# CY8C5868AXI_LP032 register map
File version: 0.1
Registers are 8-bit, read-write, no defined reset value unless marked. A register's access mark holds for its fields unless they carry their own. Offsets are from the block's base; [hi:lo] are bit positions.

## DOD_PWM_3
Base 0x400043A3
0x00 DOD_PWM_3_GLOBAL_ENABLE — PM.ACT.CFG
  [3:0] en_timer — Enable timer/counters.
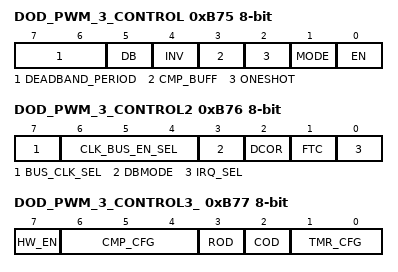
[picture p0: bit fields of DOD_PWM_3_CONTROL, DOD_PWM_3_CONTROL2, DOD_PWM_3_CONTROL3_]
0xB75 DOD_PWM_3_CONTROL — TMRx.CFG0
  [7:6] DEADBAND_PERIOD
  [5] DB — Deadband mode--Deadband phases phi1 and phi2 are outputted on CMP and TC output pins respectively.
    0=Timer (CMP and TC are output.); 1=Deadband (PHI1 (instead of CMP) and PHI2 (instead of TC) are output.)
  [4] INV — Invert sense of TIMEREN signal
  [3] CMP_BUFF — Buffer compare register. Compare register updates only on timer terminal count.
  [2] ONESHOT — Timer stops upon reaching stop condition defined by TMR_CFG bits. Can be restarted by asserting TIMER RESET or disabling and re-enabling block.
  [1] MODE — Mode. (0 = Timer; 1 = Comparator)
    0=Timer mode. CNT/CMP register holds timer count value.; 1=Comparator mode. CNT/CMP register holds comparator threshold value.
  [0] EN — Enables timer/comparator.
0xB76 DOD_PWM_3_CONTROL2 — TMRx.CFG1
  [7] BUS_CLK_SEL — Bus Clock selection.
  [6:4] CLK_BUS_EN_SEL — Digital Global Clock selection.
  [3] DBMODE — Deadband mode (asynchronous/synchronous). CMP output pin is also affected when not in deadband mode (CFG0.DEADBAND).
  [2] DCOR — Disable Clear on Read (DCOR) of Status Register SR0.
  [1] FTC — First Terminal Count (FTC). Setting this bit forces a single pulse on the TC pin when first enabled.
    0=Disable_FTC (Disable the single cycle pulse, which signifies the timer is starting.); 1=Enable_FTC (Enable the single cycle pulse, which signifies the timer is starting.)
  [0] IRQ_SEL — Irq selection. (0 = raw interrupts; 1 = status register interrupts)
0xB77 DOD_PWM_3_CONTROL3_ — TMRx.CFG2
  [7] HW_EN — When set Timer Enable controls counting.
  [6:4] CMP_CFG — Comparator configurations
    0=Equal (Compare Equal); 1=Less_than (Compare Less Than); 2=Less_than_or_equal (Compare Less Than or Equal .); 3=Greater (Compare Greater Than .); 4=Greater_than_or_equal (Compare Greater Than or Equal)
  [3] ROD — Reset On Disable (ROD). Resets internal state of output logic
  [2] COD — Clear On Disable (COD). Clears or gates outputs to zero.
  [1:0] TMR_CFG — Timer configuration (MODE = 0): 000 = Continuous; 001 = Pulsewidth; 010 = Period; 011 = Stop on IRQ
    0=Continuous (Timer runs while EN bit of CFG0 register is set to '1'.); 1=Pulsewidth (Timer runs from positive to negative edge of TIMEREN.); 2=Period (Timer runs from positive to positive edge of TIMEREN.); 3=Irq (Timer runs until IRQ.)
0xB79 DOD_PWM_3_PERIOD — TMRx.PER0 - Assigned Period
0xB7B DOD_PWM_3_COMPARE — TMRx.CNT_CMP0 - Assigned Compare Value

## DOD_PWM_1
Base 0x400043A3
0x00 DOD_PWM_1_GLOBAL_ENABLE — PM.ACT.CFG
  [3:0] en_timer — Enable timer/counters.
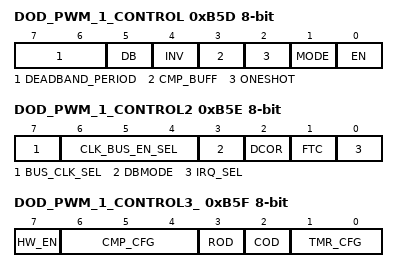
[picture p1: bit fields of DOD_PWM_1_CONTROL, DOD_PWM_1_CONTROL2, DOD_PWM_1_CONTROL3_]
0xB5D DOD_PWM_1_CONTROL — TMRx.CFG0
  [7:6] DEADBAND_PERIOD
  [5] DB — Deadband mode--Deadband phases phi1 and phi2 are outputted on CMP and TC output pins respectively.
    0=Timer (CMP and TC are output.); 1=Deadband (PHI1 (instead of CMP) and PHI2 (instead of TC) are output.)
  [4] INV — Invert sense of TIMEREN signal
  [3] CMP_BUFF — Buffer compare register. Compare register updates only on timer terminal count.
  [2] ONESHOT — Timer stops upon reaching stop condition defined by TMR_CFG bits. Can be restarted by asserting TIMER RESET or disabling and re-enabling block.
  [1] MODE — Mode. (0 = Timer; 1 = Comparator)
    0=Timer mode. CNT/CMP register holds timer count value.; 1=Comparator mode. CNT/CMP register holds comparator threshold value.
  [0] EN — Enables timer/comparator.
0xB5E DOD_PWM_1_CONTROL2 — TMRx.CFG1
  [7] BUS_CLK_SEL — Bus Clock selection.
  [6:4] CLK_BUS_EN_SEL — Digital Global Clock selection.
  [3] DBMODE — Deadband mode (asynchronous/synchronous). CMP output pin is also affected when not in deadband mode (CFG0.DEADBAND).
  [2] DCOR — Disable Clear on Read (DCOR) of Status Register SR0.
  [1] FTC — First Terminal Count (FTC). Setting this bit forces a single pulse on the TC pin when first enabled.
    0=Disable_FTC (Disable the single cycle pulse, which signifies the timer is starting.); 1=Enable_FTC (Enable the single cycle pulse, which signifies the timer is starting.)
  [0] IRQ_SEL — Irq selection. (0 = raw interrupts; 1 = status register interrupts)
0xB5F DOD_PWM_1_CONTROL3_ — TMRx.CFG2
  [7] HW_EN — When set Timer Enable controls counting.
  [6:4] CMP_CFG — Comparator configurations
    0=Equal (Compare Equal); 1=Less_than (Compare Less Than); 2=Less_than_or_equal (Compare Less Than or Equal .); 3=Greater (Compare Greater Than .); 4=Greater_than_or_equal (Compare Greater Than or Equal)
  [3] ROD — Reset On Disable (ROD). Resets internal state of output logic
  [2] COD — Clear On Disable (COD). Clears or gates outputs to zero.
  [1:0] TMR_CFG — Timer configuration (MODE = 0): 000 = Continuous; 001 = Pulsewidth; 010 = Period; 011 = Stop on IRQ
    0=Continuous (Timer runs while EN bit of CFG0 register is set to '1'.); 1=Pulsewidth (Timer runs from positive to negative edge of TIMEREN.); 2=Period (Timer runs from positive to positive edge of TIMEREN.); 3=Irq (Timer runs until IRQ.)
0xB61 DOD_PWM_1_PERIOD — TMRx.PER0 - Assigned Period
0xB63 DOD_PWM_1_COMPARE — TMRx.CNT_CMP0 - Assigned Compare Value

## DOD_PWM_4
Base 0x400043A3
0x00 DOD_PWM_4_GLOBAL_ENABLE — PM.ACT.CFG
  [3:0] en_timer — Enable timer/counters.
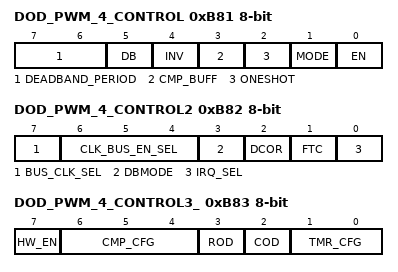
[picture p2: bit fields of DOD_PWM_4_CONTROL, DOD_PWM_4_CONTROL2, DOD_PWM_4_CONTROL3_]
0xB81 DOD_PWM_4_CONTROL — TMRx.CFG0
  [7:6] DEADBAND_PERIOD
  [5] DB — Deadband mode--Deadband phases phi1 and phi2 are outputted on CMP and TC output pins respectively.
    0=Timer (CMP and TC are output.); 1=Deadband (PHI1 (instead of CMP) and PHI2 (instead of TC) are output.)
  [4] INV — Invert sense of TIMEREN signal
  [3] CMP_BUFF — Buffer compare register. Compare register updates only on timer terminal count.
  [2] ONESHOT — Timer stops upon reaching stop condition defined by TMR_CFG bits. Can be restarted by asserting TIMER RESET or disabling and re-enabling block.
  [1] MODE — Mode. (0 = Timer; 1 = Comparator)
    0=Timer mode. CNT/CMP register holds timer count value.; 1=Comparator mode. CNT/CMP register holds comparator threshold value.
  [0] EN — Enables timer/comparator.
0xB82 DOD_PWM_4_CONTROL2 — TMRx.CFG1
  [7] BUS_CLK_SEL — Bus Clock selection.
  [6:4] CLK_BUS_EN_SEL — Digital Global Clock selection.
  [3] DBMODE — Deadband mode (asynchronous/synchronous). CMP output pin is also affected when not in deadband mode (CFG0.DEADBAND).
  [2] DCOR — Disable Clear on Read (DCOR) of Status Register SR0.
  [1] FTC — First Terminal Count (FTC). Setting this bit forces a single pulse on the TC pin when first enabled.
    0=Disable_FTC (Disable the single cycle pulse, which signifies the timer is starting.); 1=Enable_FTC (Enable the single cycle pulse, which signifies the timer is starting.)
  [0] IRQ_SEL — Irq selection. (0 = raw interrupts; 1 = status register interrupts)
0xB83 DOD_PWM_4_CONTROL3_ — TMRx.CFG2
  [7] HW_EN — When set Timer Enable controls counting.
  [6:4] CMP_CFG — Comparator configurations
    0=Equal (Compare Equal); 1=Less_than (Compare Less Than); 2=Less_than_or_equal (Compare Less Than or Equal .); 3=Greater (Compare Greater Than .); 4=Greater_than_or_equal (Compare Greater Than or Equal)
  [3] ROD — Reset On Disable (ROD). Resets internal state of output logic
  [2] COD — Clear On Disable (COD). Clears or gates outputs to zero.
  [1:0] TMR_CFG — Timer configuration (MODE = 0): 000 = Continuous; 001 = Pulsewidth; 010 = Period; 011 = Stop on IRQ
    0=Continuous (Timer runs while EN bit of CFG0 register is set to '1'.); 1=Pulsewidth (Timer runs from positive to negative edge of TIMEREN.); 2=Period (Timer runs from positive to positive edge of TIMEREN.); 3=Irq (Timer runs until IRQ.)
0xB85 DOD_PWM_4_PERIOD — TMRx.PER0 - Assigned Period
0xB87 DOD_PWM_4_COMPARE — TMRx.CNT_CMP0 - Assigned Compare Value
